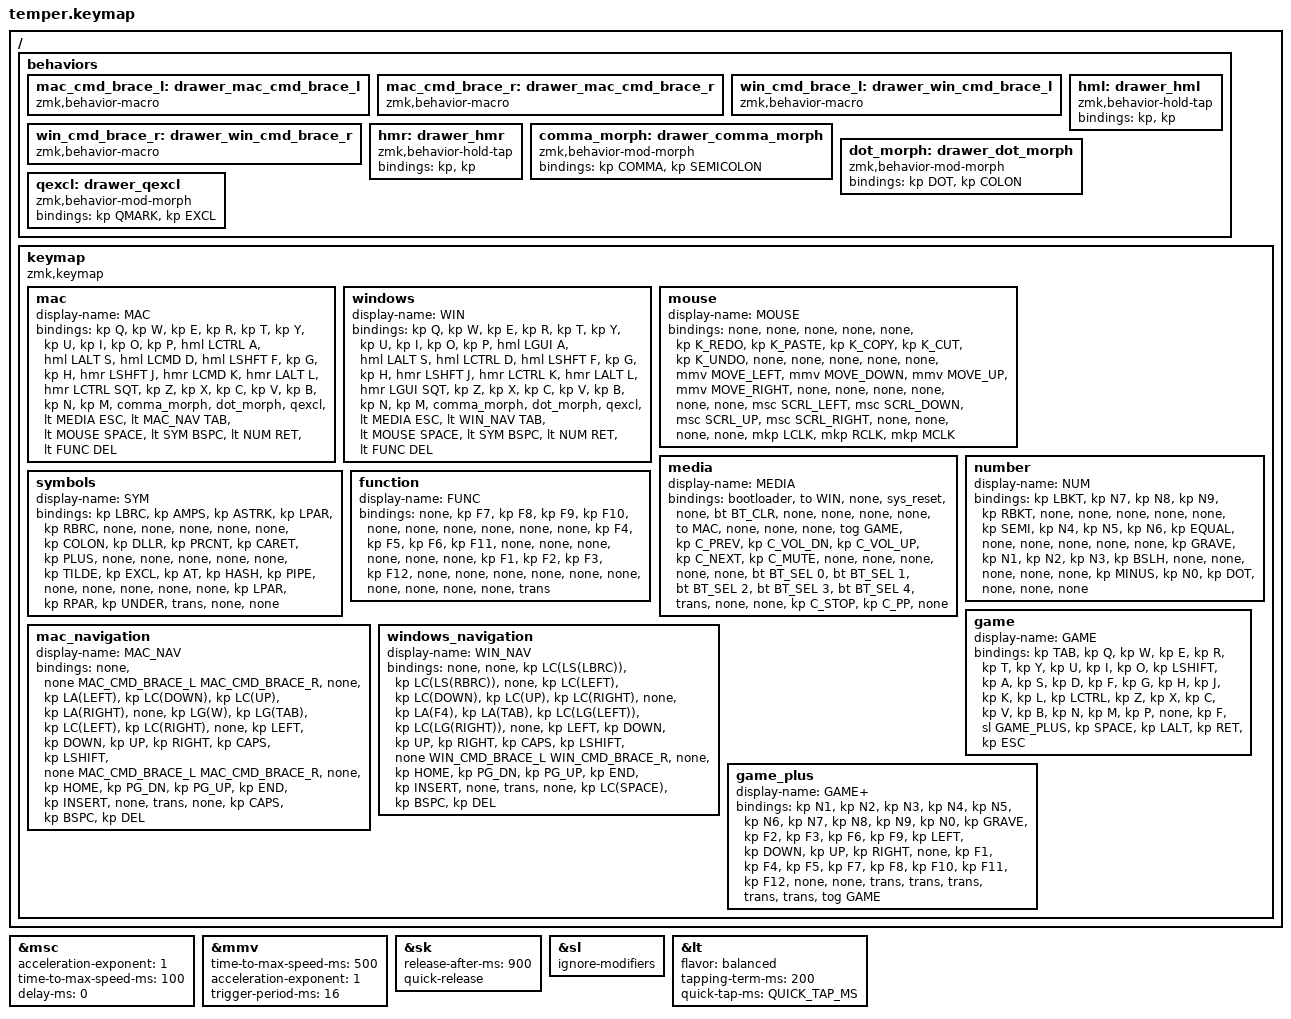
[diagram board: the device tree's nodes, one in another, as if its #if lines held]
/*
 * Copyright (c) 2024 The ZMK Contributors
 * SPDX-License-Identifier: MIT
 *
 * Temper keymap — ported from Eyelash Sofle (urob)
 */

#define ZMK_POINTING_DEFAULT_MOVE_VAL 2400
#define ZMK_POINTING_DEFAULT_SCRL_VAL 25

#include <behaviors.dtsi>
#include <zmk-helpers/helper.h>
#include <dt-bindings/zmk/keys.h>
#include <dt-bindings/zmk/bt.h>
#include <dt-bindings/zmk/pointing.h>

/* ── Key position indices ──────────────────────────────────────────
 *
 * ╭─────────────────────╮ ╭─────────────────────╮
 * │ LT4 LT3 LT2 LT1 LT0 │ │ RT0 RT1 RT2 RT3 RT4 │
 * │ LM4 LM3 LM2 LM1 LM0 │ │ RM0 RM1 RM2 RM3 RM4 │
 * │ LB4 LB3 LB2 LB1 LB0 │ │ RB0 RB1 RB2 RB3 RB4 │
 * ╰───────╮ LH2 LH1 LH0 │ │ RH0 RH1 RH2 ╭───────╯
 *         ╰─────────────╯ ╰─────────────╯
 *
 * Numeric:   0  1  2  3  4  |  5  6  7  8  9
 *           10 11 12 13 14  | 15 16 17 18 19
 *           20 21 22 23 24  | 25 26 27 28 29
 *               30 31 32    |    33 34 35         */

#define LT4  0
#define LT3  1
#define LT2  2
#define LT1  3
#define LT0  4
#define RT0  5
#define RT1  6
#define RT2  7
#define RT3  8
#define RT4  9
#define LM4 10
#define LM3 11
#define LM2 12
#define LM1 13
#define LM0 14
#define RM0 15
#define RM1 16
#define RM2 17
#define RM3 18
#define RM4 19
#define LB4 20
#define LB3 21
#define LB2 22
#define LB1 23
#define LB0 24
#define RB0 25
#define RB1 26
#define RB2 27
#define RB3 28
#define RB4 29
#define LH2 30
#define LH1 31
#define LH0 32
#define RH0 33
#define RH1 34
#define RH2 35

#define KEYS_L LT4 LT3 LT2 LT1 LT0  LM4 LM3 LM2 LM1 LM0  LB4 LB3 LB2 LB1 LB0
#define KEYS_R RT0 RT1 RT2 RT3 RT4  RM0 RM1 RM2 RM3 RM4  RB0 RB1 RB2 RB3 RB4
#define THUMBS LH2 LH1 LH0  RH0 RH1 RH2

/* ── Layer indices ───────────────────────────────────────────────── */
#define MAC       0
#define WIN       1
#define MOUSE     2
#define MEDIA     3
#define NUM       4
#define SYM       5
#define FUNC      6
#define MAC_NAV   7
#define WIN_NAV   8
#define GAME      9
#define GAME_PLUS 10

#define QUICK_TAP_MS 175

/* Keep the identical HID action visibly OS-specific in the keymap drawing. */
#ifdef KEYMAP_DRAWER
/ {
    behaviors {
        mac_cmd_brace_l: drawer_mac_cmd_brace_l { compatible = "zmk,behavior-macro"; #binding-cells = <0>; };
        mac_cmd_brace_r: drawer_mac_cmd_brace_r { compatible = "zmk,behavior-macro"; #binding-cells = <0>; };
        win_cmd_brace_l: drawer_win_cmd_brace_l { compatible = "zmk,behavior-macro"; #binding-cells = <0>; };
        win_cmd_brace_r: drawer_win_cmd_brace_r { compatible = "zmk,behavior-macro"; #binding-cells = <0>; };
    };
};
#define MAC_CMD_BRACE_L &mac_cmd_brace_l
#define MAC_CMD_BRACE_R &mac_cmd_brace_r
#define WIN_CMD_BRACE_L &win_cmd_brace_l
#define WIN_CMD_BRACE_R &win_cmd_brace_r
#else
#define MAC_CMD_BRACE_L &kp LG(LS(LBRC))
#define MAC_CMD_BRACE_R &kp LG(LS(RBRC))
#define WIN_CMD_BRACE_L &kp LG(LS(LBRC))
#define WIN_CMD_BRACE_R &kp LG(LS(RBRC))
#endif

/* ── Mouse pointer timing ────────────────────────────────────────── */
&msc {
    acceleration-exponent = <1>;
    time-to-max-speed-ms = <100>;
    delay-ms = <0>;
};
&mmv {
    time-to-max-speed-ms = <500>;
    acceleration-exponent = <1>;
    trigger-period-ms = <16>;
};

/* ── Tweak built-in behaviors ────────────────────────────────────── */
&sk {
    release-after-ms = <900>;
    quick-release;
};
&sl {
    ignore-modifiers;  // Allow sticky mods to chord across sticky layers.
};
&lt {
    flavor = "balanced";
    tapping-term-ms = <200>;
    quick-tap-ms = <QUICK_TAP_MS>;
};

/* ── Home Row Mods (HRMs) ────────────────────────────────────────── */
/* keymap-drawer cannot expand the nested helper macros below. Give it
 * equivalent parser-only nodes; normal ZMK builds still use the full code. */
#ifdef KEYMAP_DRAWER
/ {
    behaviors {
        hml: drawer_hml {
            compatible = "zmk,behavior-hold-tap";
            bindings = <&kp>, <&kp>;
        };
        hmr: drawer_hmr {
            compatible = "zmk,behavior-hold-tap";
            bindings = <&kp>, <&kp>;
        };
        comma_morph: drawer_comma_morph {
            compatible = "zmk,behavior-mod-morph";
            bindings = <&kp COMMA>, <&kp SEMICOLON>;
        };
        dot_morph: drawer_dot_morph {
            compatible = "zmk,behavior-mod-morph";
            bindings = <&kp DOT>, <&kp COLON>;
        };
        qexcl: drawer_qexcl {
            compatible = "zmk,behavior-mod-morph";
            bindings = <&kp QMARK>, <&kp EXCL>;
        };
    };
};
#else
#define MAKE_HRM(NAME, HOLD, TAP, TRIGGER_POS)                          \
    ZMK_HOLD_TAP(NAME,                                                   \
        bindings = <HOLD>, <TAP>;                                        \
        flavor = "balanced";                                             \
        tapping-term-ms = <280>;                                         \
        quick-tap-ms = <QUICK_TAP_MS>;                                   \
        require-prior-idle-ms = <150>;                                   \
        hold-trigger-on-release;                                         \
        hold-trigger-key-positions = <TRIGGER_POS>;)

MAKE_HRM(hml, &kp, &kp, KEYS_R THUMBS)  // Left-hand HRMs.
MAKE_HRM(hmr, &kp, &kp, KEYS_L THUMBS)  // Right-hand HRMs.

// Make HRM combo bindings tap-only to allow instantaneous mod chording.
#define ZMK_COMBO_8(NAME, TAP, POS, LAYERS, COMBO_MS, IDLE_MS, HOLD, SIDE) \
    MAKE_HRM(hm_combo_##NAME, &kp, TAP, SIDE THUMBS)                        \
    ZMK_COMBO_6(NAME, &hm_combo_##NAME HOLD 0, POS, LAYERS, COMBO_MS, IDLE_MS)

#include "combos.dtsi"

/* ── Magic-shift & adaptive repeat ──────────────────────────────── */
// Tap: sticky-shift (or repeat after alpha) | Shift+tap: caps-word | Hold: shift.
#define MAGIC_SHIFT &magic_shift LSHFT 0
ZMK_HOLD_TAP(magic_shift,
    bindings = <&kp>, <&magic_shift_tap>;
    flavor = "balanced";
    tapping-term-ms = <200>;
    quick-tap-ms = <QUICK_TAP_MS>;)
ZMK_MOD_MORPH(magic_shift_tap,
    bindings = <&shift_repeat>, <&caps_word>;
    mods = <(MOD_LSFT)>;)
ZMK_ADAPTIVE_KEY(
    shift_repeat, bindings = <&sk LSHFT>;
    repeat {
        trigger-keys = <A B C D E F G H I J K L M N O P Q R S T U V W X Y Z>;
        bindings = <&key_repeat>;
        max-prior-idle-ms = <1200>;
        strict-modifiers;
    };)
&caps_word {
    /delete-property/ ignore-modifiers;
};

/* ── Mod-morphs ──────────────────────────────────────────────────── */
#define SIMPLE_MORPH(NAME, MOD, BINDING1, BINDING2)       \
    ZMK_MOD_MORPH(NAME,                                    \
        mods = <(MOD_L##MOD | MOD_R##MOD)>;                \
        bindings = <BINDING1>, <BINDING2>;)

SIMPLE_MORPH(comma_morph,       SFT, &kp COMMA,     &kp SEMICOLON)
SIMPLE_MORPH(dot_morph,         SFT, &kp DOT,       &kp COLON)
SIMPLE_MORPH(qexcl,             SFT, &kp QMARK,     &kp EXCL)
SIMPLE_MORPH(lpar_lt,           SFT, &kp LPAR,      &kp LT)
SIMPLE_MORPH(rpar_gt,           SFT, &kp RPAR,      &kp GT)
#endif

/* ── Keymap ──────────────────────────────────────────────────────── */
/ {
    keymap {
        compatible = "zmk,keymap";

        mac {
            display-name = "MAC";
            bindings = <
// ╭──────────────┬──────────────┬──────────────┬──────────────┬──────────────╮   ╭──────────────┬──────────────┬──────────────┬──────────────┬──────────────╮
    &kp Q          &kp W          &kp E          &kp R          &kp T              &kp Y          &kp U          &kp I          &kp O          &kp P
    &hml LCTRL A   &hml LALT S    &hml LCMD D    &hml LSHFT F   &kp G              &kp H          &hmr LSHFT J   &hmr LCMD K    &hmr LALT L    &hmr LCTRL SQT
    &kp Z          &kp X          &kp C          &kp V          &kp B              &kp N          &kp M          &comma_morph   &dot_morph     &qexcl
// ╰──────────────┴──────────────┼──────────────┼──────────────┼──────────────╯   ╰──────────────┼──────────────┼──────────────┼──────────────┴──────────────╯
                                  &lt MEDIA ESC  &lt MAC_NAV TAB &lt MOUSE SPACE      &lt SYM BSPC   &lt NUM RET    &lt FUNC DEL
//                               ╰──────────────┴──────────────┴──────────────╯   ╰──────────────┴──────────────┴──────────────╯
            >;
        };

        windows {
            display-name = "WIN";
            bindings = <
// ╭──────────────┬──────────────┬──────────────┬──────────────┬──────────────╮   ╭──────────────┬──────────────┬──────────────┬──────────────┬──────────────╮
    &kp Q          &kp W          &kp E          &kp R          &kp T              &kp Y          &kp U          &kp I          &kp O          &kp P
    &hml LGUI A    &hml LALT S    &hml LCTRL D   &hml LSHFT F   &kp G              &kp H          &hmr LSHFT J   &hmr LCTRL K   &hmr LALT L    &hmr LGUI SQT
    &kp Z          &kp X          &kp C          &kp V          &kp B              &kp N          &kp M          &comma_morph   &dot_morph     &qexcl
// ╰──────────────┴──────────────┼──────────────┼──────────────┼──────────────╯   ╰──────────────┼──────────────┼──────────────┼──────────────┴──────────────╯
                                  &lt MEDIA ESC  &lt WIN_NAV TAB &lt MOUSE SPACE      &lt SYM BSPC   &lt NUM RET    &lt FUNC DEL
//                               ╰──────────────┴──────────────┴──────────────╯   ╰──────────────┴──────────────┴──────────────╯
            >;
        };

        mouse {
            display-name = "MOUSE";
            bindings = <
// ╭──────────────┬──────────────┬──────────────┬──────────────┬──────────────╮   ╭──────────────┬──────────────┬──────────────┬──────────────┬──────────────╮
    &none          &none          &none          &none          &none              &kp K_REDO     &kp K_PASTE    &kp K_COPY     &kp K_CUT      &kp K_UNDO
    &none          &none          &none          &none          &none              &mmv MOVE_LEFT &mmv MOVE_DOWN &mmv MOVE_UP   &mmv MOVE_RIGHT &none
    &none          &none          &none          &none          &none              &msc SCRL_LEFT &msc SCRL_DOWN &msc SCRL_UP   &msc SCRL_RIGHT &none
                                  &none          &none          &none              &mkp LCLK      &mkp RCLK      &mkp MCLK
            >;
        };

        media {
            display-name = "MEDIA";
            bindings = <
// ╭──────────────┬──────────────┬──────────────┬──────────────┬──────────────╮   ╭──────────────┬──────────────┬──────────────┬──────────────┬──────────────╮
    &bootloader    &to WIN        &none          &sys_reset     &none              &bt BT_CLR     &none          &none          &none          &none
    &to MAC        &none          &none          &none          &tog GAME          &kp C_PREV     &kp C_VOL_DN   &kp C_VOL_UP   &kp C_NEXT     &kp C_MUTE
    &none          &none          &none          &none          &none              &bt BT_SEL 0   &bt BT_SEL 1   &bt BT_SEL 2   &bt BT_SEL 3   &bt BT_SEL 4
                                  &trans         &none          &none              &kp C_STOP     &kp C_PP       &none
            >;
        };

        number {
            display-name = "NUM";
            bindings = <
// ╭──────────────┬──────────────┬──────────────┬──────────────┬──────────────╮   ╭──────────────┬──────────────┬──────────────┬──────────────┬──────────────╮
    &kp LBKT       &kp N7         &kp N8         &kp N9         &kp RBKT           &none          &none          &none          &none          &none
    &kp SEMI       &kp N4         &kp N5         &kp N6         &kp EQUAL          &none          &none          &none          &none          &none
    &kp GRAVE      &kp N1         &kp N2         &kp N3         &kp BSLH           &none          &none          &none          &none          &none
                                  &kp MINUS      &kp N0         &kp DOT            &none          &none          &none
            >;
        };

        symbols {
            display-name = "SYM";
            bindings = <
// ╭──────────────┬──────────────┬──────────────┬──────────────┬──────────────╮   ╭──────────────┬──────────────┬──────────────┬──────────────┬──────────────╮
    &kp LBRC       &kp AMPS       &kp ASTRK      &kp LPAR       &kp RBRC           &none          &none          &none          &none          &none
    &kp COLON      &kp DLLR       &kp PRCNT      &kp CARET      &kp PLUS           &none          &none          &none          &none          &none
    &kp TILDE      &kp EXCL       &kp AT         &kp HASH       &kp PIPE           &none          &none          &none          &none          &none
                                  &kp LPAR       &kp RPAR       &kp UNDER          &trans         &none          &none
            >;
        };

        function {
            display-name = "FUNC";
            bindings = <
// ╭──────────────┬──────────────┬──────────────┬──────────────┬──────────────╮   ╭──────────────┬──────────────┬──────────────┬──────────────┬──────────────╮
    &none          &kp F7         &kp F8         &kp F9         &kp F10            &none          &none          &none          &none          &none
    &none          &kp F4         &kp F5         &kp F6         &kp F11            &none          &none          &none          &none          &none
    &none          &kp F1         &kp F2         &kp F3         &kp F12            &none          &none          &none          &none          &none
                                  &none          &none          &none              &none          &none          &trans
            >;
        };

        mac_navigation {
            display-name = "MAC_NAV";
            bindings = <
// ╭──────────────┬──────────────┬──────────────┬──────────────┬──────────────╮   ╭──────────────┬──────────────┬──────────────┬──────────────┬──────────────╮
    &none          &none          MAC_CMD_BRACE_L   MAC_CMD_BRACE_R   &none          &kp LA(LEFT)   &kp LC(DOWN)  &kp LC(UP)    &kp LA(RIGHT)  &none
    &kp LG(W)      &kp LG(TAB)    &kp LC(LEFT)     &kp LC(RIGHT)    &none          &kp LEFT       &kp DOWN      &kp UP        &kp RIGHT      &kp CAPS
    &kp LSHIFT     &none          MAC_CMD_BRACE_L   MAC_CMD_BRACE_R   &none          &kp HOME       &kp PG_DN     &kp PG_UP     &kp END        &kp INSERT
                                  &none             &trans            &none          &kp CAPS       &kp BSPC      &kp DEL
            >;
        };

        windows_navigation {
            display-name = "WIN_NAV";
            bindings = <
// ╭──────────────┬──────────────┬──────────────┬──────────────┬──────────────╮   ╭──────────────┬──────────────┬──────────────┬──────────────┬──────────────╮
    &none          &none          &kp LC(LS(LBRC)) &kp LC(LS(RBRC)) &none          &kp LC(LEFT)   &kp LC(DOWN)  &kp LC(UP)    &kp LC(RIGHT)  &none
    &kp LA(F4)     &kp LA(TAB)    &kp LC(LG(LEFT)) &kp LC(LG(RIGHT)) &none         &kp LEFT       &kp DOWN      &kp UP        &kp RIGHT      &kp CAPS
    &kp LSHIFT     &none          WIN_CMD_BRACE_L   WIN_CMD_BRACE_R   &none          &kp HOME       &kp PG_DN     &kp PG_UP     &kp END        &kp INSERT
                                  &none             &trans            &none          &kp LC(SPACE)  &kp BSPC      &kp DEL
            >;
        };

        game {
            display-name = "GAME";
            bindings = <
// ╭──────────────┬──────────────┬──────────────┬──────────────┬──────────────╮   ╭──────────────┬──────────────┬──────────────┬──────────────┬──────────────╮
    &kp TAB        &kp Q          &kp W          &kp E          &kp R              &kp T          &kp Y          &kp U          &kp I          &kp O
    &kp LSHIFT     &kp A          &kp S          &kp D          &kp F               &kp G          &kp H          &kp J          &kp K          &kp L
    &kp LCTRL      &kp Z          &kp X          &kp C          &kp V              &kp B          &kp N          &kp M          &kp P          &none
                                  &kp F          &sl GAME_PLUS  &kp SPACE          &kp LALT       &kp RET        &kp ESC
            >;
        };

        game_plus {
            display-name = "GAME+";
            bindings = <
// ╭──────────────┬──────────────┬──────────────┬──────────────┬──────────────╮   ╭──────────────┬──────────────┬──────────────┬──────────────┬──────────────╮
    &kp N1         &kp N2         &kp N3         &kp N4         &kp N5             &kp N6         &kp N7         &kp N8         &kp N9         &kp N0
    &kp GRAVE      &kp F2         &kp F3         &kp F6         &kp F9             &kp LEFT       &kp DOWN       &kp UP         &kp RIGHT      &none
    &kp F1         &kp F4         &kp F5         &kp F7         &kp F8             &kp F10        &kp F11        &kp F12        &none          &none
                                  &trans         &trans         &trans             &trans         &trans         &tog GAME
            >;
        };

    };
};
